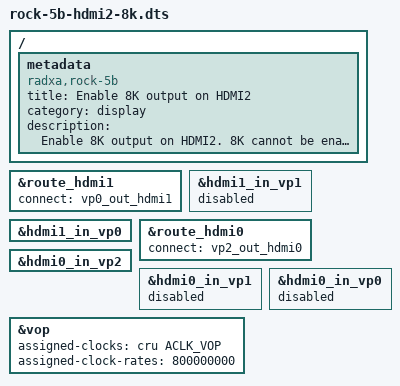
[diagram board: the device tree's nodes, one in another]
/dts-v1/;
/plugin/;
#include <dt-bindings/clock/rk3588-cru.h>

/ {
	metadata {
		title = "Enable 8K output on HDMI2";
		compatible = "radxa,rock-5b";
		category = "display";
		description = "Enable 8K output on HDMI2.
8K cannot be enabled on HDMI1 and HDMI2 at the same time.";
	};
};

&route_hdmi1 {
	connect = <&vp0_out_hdmi1>;
	status = "okay";
};

&hdmi1_in_vp1 {
	status = "disabled";
};

&hdmi1_in_vp0 {
	status = "okay";
};

&route_hdmi0 {
	connect = <&vp2_out_hdmi0>;
	status = "okay";
};

&hdmi0_in_vp2 {
	status = "okay";
};

&hdmi0_in_vp1 {
	status = "disabled";
};

&hdmi0_in_vp0 {
	status = "disabled";
};

&vop {
	assigned-clocks = <&cru ACLK_VOP>;
	assigned-clock-rates = <800000000>;
};
